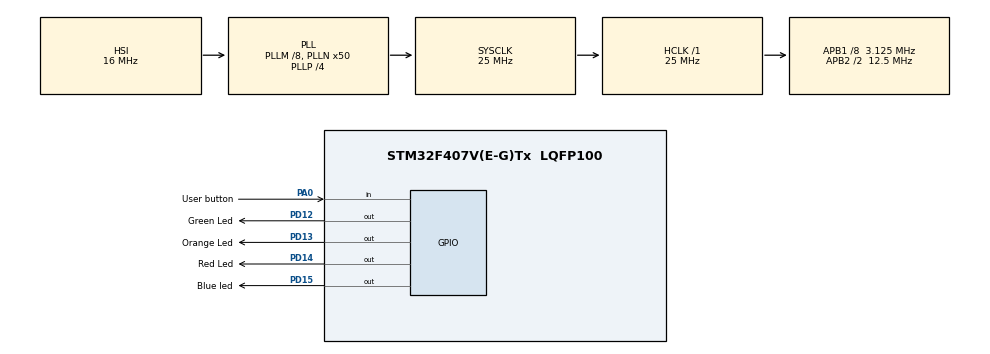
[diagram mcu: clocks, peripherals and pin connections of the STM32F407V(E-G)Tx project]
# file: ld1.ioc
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Mcu.Family=STM32F4
Mcu.Name=STM32F407V(E-G)Tx
Mcu.Package=LQFP100
NVIC.PriorityGroup=NVIC_PRIORITYGROUP_0
PA0-WKUP.GPIO_Label=User button
PA0-WKUP.Signal=GPIO_Input
PD12.GPIO_Label=Green Led
PD12.Signal=GPIO_Output
PD13.GPIO_Label=Orange Led
PD13.Signal=GPIO_Output
PD14.GPIO_Label=Red Led
PD14.Signal=GPIO_Output
PD15.GPIO_Label=Blue led
PD15.Signal=GPIO_Output
ProjectManager.HeapSize=0x200
ProjectManager.StackSize=0x400
ProjectManager.TargetToolchain=STM32CubeIDE
RCC.48MHZClocksFreq_Value=14285714.285714285
RCC.AHBFreq_Value=25000000
RCC.APB1CLKDivider=RCC_HCLK_DIV8
RCC.APB1Freq_Value=3125000
RCC.APB1TimFreq_Value=6250000
RCC.APB2CLKDivider=RCC_HCLK_DIV2
RCC.APB2Freq_Value=12500000
RCC.APB2TimFreq_Value=25000000
RCC.CortexFreq_Value=25000000
RCC.HCLKFreq_Value=25000000
RCC.HSE_VALUE=8000000
RCC.HSI_VALUE=16000000
RCC.PLLM=8
RCC.PLLN=50
RCC.PLLP=RCC_PLLP_DIV4
RCC.PLLQ=7
RCC.SYSCLKFreq_VALUE=25000000
RCC.SYSCLKSource=RCC_SYSCLKSOURCE_PLLCLK
RCC.VCOOutputFreq_Value=100000000
board=STM32F407G-DISC1

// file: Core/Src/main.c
/* USER CODE BEGIN Header */
/**
  ******************************************************************************
  * @file           : main.c
  * @brief          : Main program body
  ******************************************************************************
  * @attention
  *
  * Copyright (c) 2024 STMicroelectronics.
  * All rights reserved.
  *
  * This software is licensed under terms that can be found in the LICENSE file
  * in the root directory of this software component.
  * If no LICENSE file comes with this software, it is provided AS-IS.
  *
  ******************************************************************************
  */
/* USER CODE END Header */
#include "main.h"

void SystemClock_Config(void);
void GPIO_Init(void);
static void MX_GPIO_Init(void);

int main(void)
{

  /* MCU Configuration--------------------------------------------------------*/

  /* Reset of all peripherals, Initializes the Flash interface and the Systick. */
  HAL_Init();

  /* Configure the system clock */
  SystemClock_Config();

  /* Initialize all configured peripherals */
  MX_GPIO_Init();
  /* USER CODE BEGIN 2 */
  	GPIO_Init();
  	int uzd = 3;
    int daznis = 1000;
    while (1) {
  	  if (uzd == 1) {
  	  	  GPIOD->ODR &= ~(1 << 15);
  	  	  GPIOD->ODR &= ~(1 << 12);
  	  	  HAL_Delay(1000);

  	  	  GPIOD->ODR ^= 1<<15;
            HAL_Delay(1000);

  	  	  GPIOD->ODR ^= 1<<12;
  	  	  HAL_Delay(1000);
  	  }
  	  else if (uzd == 2) {
          	 GPIOD->ODR ^= 1<<13;
          	 GPIOD->ODR ^= 1<<14;
          	 HAL_Delay(1000);
          	 GPIOD->ODR &= ~(1 << 14);
          	 HAL_Delay(1000);
          	 GPIOD->ODR ^= 1<<14;
          	 HAL_Delay(1000);
          	 GPIOD->ODR &= ~(1 << 13);
          	 GPIOD->ODR &= ~(1 << 14);
  			 HAL_Delay(1000);
          	 GPIOD->ODR ^= 1<<14;
          	 HAL_Delay(1000);
          	 GPIOD->ODR &= ~(1 << 14);
  			 HAL_Delay(1000);
           }
  	  else if (uzd == 3) {
  		  GPIOD->ODR &= ~(1 << 15);
  		  if (GPIOA->IDR & GPIO_PIN_0) {
  			  GPIOD->ODR ^= 1<<15;
  		  }
  	  }
  	  else if (uzd == 4) {
  		  GPIOD->ODR |= (1 << 13);
  		  HAL_Delay(daznis);
  		  GPIOD->ODR &= ~(1 << 13);
  		  HAL_Delay(daznis);

  		  if (GPIOA->IDR & GPIO_PIN_0) {
  		  	daznis = daznis + 500;
  		  }
  	  }

        }
  /* USER CODE END 3 */
}

void SystemClock_Config(void)
{
  RCC_OscInitTypeDef RCC_OscInitStruct = {0};
  RCC_ClkInitTypeDef RCC_ClkInitStruct = {0};

  /** Configure the main internal regulator output voltage
  */
  __HAL_RCC_PWR_CLK_ENABLE();
  __HAL_PWR_VOLTAGESCALING_CONFIG(PWR_REGULATOR_VOLTAGE_SCALE1);

  /** Initializes the RCC Oscillators according to the specified parameters
  * in the RCC_OscInitTypeDef structure.
  */
  RCC_OscInitStruct.OscillatorType = RCC_OSCILLATORTYPE_HSI;
  RCC_OscInitStruct.HSIState = RCC_HSI_ON;
  RCC_OscInitStruct.HSICalibrationValue = RCC_HSICALIBRATION_DEFAULT;
  RCC_OscInitStruct.PLL.PLLState = RCC_PLL_ON;
  RCC_OscInitStruct.PLL.PLLSource = RCC_PLLSOURCE_HSI;
  RCC_OscInitStruct.PLL.PLLM = 8;
  RCC_OscInitStruct.PLL.PLLN = 50;
  RCC_OscInitStruct.PLL.PLLP = RCC_PLLP_DIV4;
  RCC_OscInitStruct.PLL.PLLQ = 7;
  if (HAL_RCC_OscConfig(&RCC_OscInitStruct) != HAL_OK)
  {
    Error_Handler();
  }

  /** Initializes the CPU, AHB and APB buses clocks
  */
  RCC_ClkInitStruct.ClockType = RCC_CLOCKTYPE_HCLK|RCC_CLOCKTYPE_SYSCLK
                              |RCC_CLOCKTYPE_PCLK1|RCC_CLOCKTYPE_PCLK2;
  RCC_ClkInitStruct.SYSCLKSource = RCC_SYSCLKSOURCE_PLLCLK;
  RCC_ClkInitStruct.AHBCLKDivider = RCC_SYSCLK_DIV1;
  RCC_ClkInitStruct.APB1CLKDivider = RCC_HCLK_DIV8;
  RCC_ClkInitStruct.APB2CLKDivider = RCC_HCLK_DIV2;

  if (HAL_RCC_ClockConfig(&RCC_ClkInitStruct, FLASH_LATENCY_0) != HAL_OK)
  {
    Error_Handler();
  }
}

static void MX_GPIO_Init(void)
{
  GPIO_InitTypeDef GPIO_InitStruct = {0};

  /* GPIO Ports Clock Enable */
  __HAL_RCC_GPIOA_CLK_ENABLE();
  __HAL_RCC_GPIOD_CLK_ENABLE();

  /*Configure GPIO pin Output Level */
  HAL_GPIO_WritePin(GPIOD, Green_Led_Pin|Orange_Led_Pin|Red_Led_Pin|Blue_led_Pin, GPIO_PIN_RESET);

  /*Configure GPIO pin : User_button_Pin */
  GPIO_InitStruct.Pin = User_button_Pin;
  GPIO_InitStruct.Mode = GPIO_MODE_INPUT;
  GPIO_InitStruct.Pull = GPIO_NOPULL;
  HAL_GPIO_Init(User_button_GPIO_Port, &GPIO_InitStruct);

  /*Configure GPIO pins : Green_Led_Pin Orange_Led_Pin Red_Led_Pin Blue_led_Pin */
  GPIO_InitStruct.Pin = Green_Led_Pin|Orange_Led_Pin|Red_Led_Pin|Blue_led_Pin;
  GPIO_InitStruct.Mode = GPIO_MODE_OUTPUT_PP;
  GPIO_InitStruct.Pull = GPIO_NOPULL;
  GPIO_InitStruct.Speed = GPIO_SPEED_FREQ_LOW;
  HAL_GPIO_Init(GPIOD, &GPIO_InitStruct);

}

/* USER CODE BEGIN 4 */
void GPIO_Init(void) {
    // Enable GPIO port D clock
    RCC->AHB1ENR |= RCC_AHB1ENR_GPIODEN;

    // Configure GPIO D pins 12, 13, 14, 15 as output
    GPIOD->MODER |= (GPIO_MODER_MODER12_0 | GPIO_MODER_MODER13_0 |
                     GPIO_MODER_MODER14_0 | GPIO_MODER_MODER15_0);

    // Configure GPIO D output type as push-pull
    GPIOD->OTYPER &= ~(GPIO_OTYPER_OT_12 | GPIO_OTYPER_OT_13 |
                       GPIO_OTYPER_OT_14 | GPIO_OTYPER_OT_15);

    // Configure GPIO D output speed (low speed)
    GPIOD->OSPEEDR &= ~(GPIO_OSPEEDR_OSPEED12 | GPIO_OSPEEDR_OSPEED13 |
                        GPIO_OSPEEDR_OSPEED14 | GPIO_OSPEEDR_OSPEED15);

    // Configure GPIO D pull-up/pull-down as no pull-up/pull-down
    GPIOD->PUPDR &= ~(GPIO_PUPDR_PUPD12 | GPIO_PUPDR_PUPD13 |
                      GPIO_PUPDR_PUPD14 | GPIO_PUPDR_PUPD15);

    // Initialize GPIO D output data register to reset all pins
    GPIOD->ODR &= ~(GPIO_ODR_OD12 | GPIO_ODR_OD13 |
                    GPIO_ODR_OD14 | GPIO_ODR_OD15);

    // Enable GPIO port A clock
    RCC->AHB1ENR |= RCC_AHB1ENR_GPIOAEN;

    // No need to configure GPIOA as it's for input
}
/* USER CODE END 4 */

void Error_Handler(void)
{
  __disable_irq();
  while (1)
  {
  }
}
